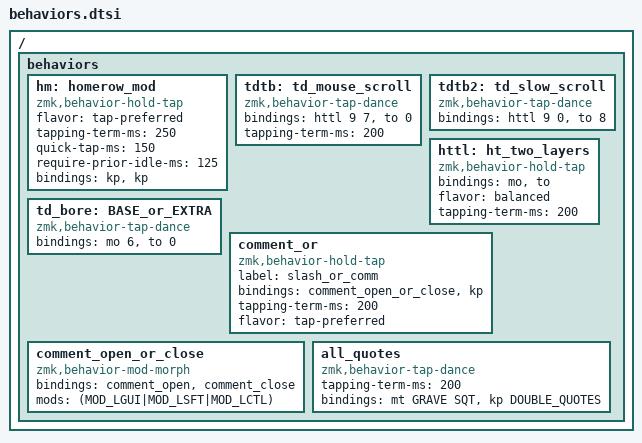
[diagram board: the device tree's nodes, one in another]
/ {
    behaviors {

        hm: homerow_mod {
            compatible = "zmk,behavior-hold-tap";
            #binding-cells = <2>;
            flavor = "tap-preferred";
            tapping-term-ms = <250>;
            quick-tap-ms = <150>;
            require-prior-idle-ms = <125>;
            bindings = <&kp>, <&kp>;
        };

        tdtb: td_mouse_scroll {
            compatible = "zmk,behavior-tap-dance";
            #binding-cells = <0>;
            bindings = <&httl 9 7>, <&to 0>;
            tapping-term-ms = <200>;
        };

        tdtb2: td_slow_scroll {
            compatible = "zmk,behavior-tap-dance";
            #binding-cells = <0>;
            bindings = <&httl 9 0>, <&to 8>;
        };

        httl: ht_two_layers {
            compatible = "zmk,behavior-hold-tap";
            bindings = <&mo>, <&to>;

            #binding-cells = <2>;
            flavor = "balanced";
            tapping-term-ms = <200>;
        };

        td_bore: BASE_or_EXTRA {
            compatible = "zmk,behavior-tap-dance";
            #binding-cells = <0>;
            bindings = <&mo 6>, <&to 0>;
        };

        comment_or: comment_or {
            compatible = "zmk,behavior-hold-tap";
            label = "slash_or_comm";
            bindings = <&comment_open_or_close>, <&kp>;

            #binding-cells = <2>;
            tapping-term-ms = <200>;
            flavor = "tap-preferred";
        };

        comment_open_or_close: comment_open_or_close {
            compatible = "zmk,behavior-mod-morph";
            #binding-cells = <0>;
            bindings = <&comment_open>, <&comment_close>;
            mods = <(MOD_LGUI|MOD_LSFT|MOD_LCTL)>;
        };

        all_quotes: all_quotes {
            compatible = "zmk,behavior-tap-dance";
            #binding-cells = <0>;
            tapping-term-ms = <200>;
            bindings = <&mt GRAVE SQT>, <&kp DOUBLE_QUOTES>;
        };

    };
};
